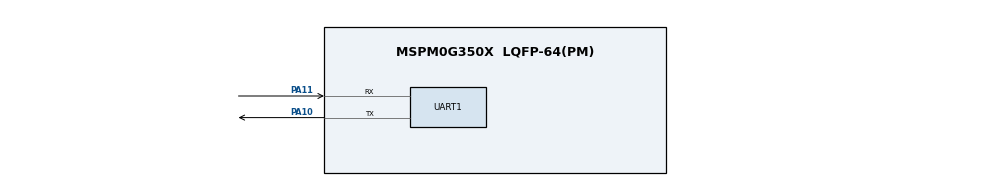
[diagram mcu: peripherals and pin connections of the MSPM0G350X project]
/**
 * @cliArgs --device "MSPM0G350X" --package "LQFP-64(PM)" --part "Default" --product "mspm0_sdk@2.01.00.03"
 * @versions {"tool":"1.20.0+3587"}
 */

/**
 * Import the modules used in this configuration.
 */
const GPIO    = scripting.addModule("/ti/driverlib/GPIO", {}, false);
const GPIO1   = GPIO.addInstance();
const GPIO2   = GPIO.addInstance();
const GPIO3   = GPIO.addInstance();
const SYSCTL  = scripting.addModule("/ti/driverlib/SYSCTL");
const SYSTICK = scripting.addModule("/ti/driverlib/SYSTICK");
const TIMER   = scripting.addModule("/ti/driverlib/TIMER", {}, false);
const TIMER1  = TIMER.addInstance();
const UART    = scripting.addModule("/ti/driverlib/UART", {}, false);
const UART1   = UART.addInstance();

/**
 * Write custom configuration values to the imported modules.
 */
const divider7       = system.clockTree["PLL_PDIV"];
divider7.divideValue = 2;

const divider9       = system.clockTree["UDIV"];
divider9.divideValue = 2;

const gate7  = system.clockTree["MFCLKGATE"];
gate7.enable = true;

const multiplier2         = system.clockTree["PLL_QDIV"];
multiplier2.multiplyValue = 5;

const mux8       = system.clockTree["HSCLKMUX"];
mux8.inputSelect = "HSCLKMUX_SYSPLL2X";

GPIO1.$name                              = "LED1";
GPIO1.port                               = "PORTB";
GPIO1.associatedPins[0].$name            = "PIN_0";
GPIO1.associatedPins[0].internalResistor = "PULL_DOWN";
GPIO1.associatedPins[0].assignedPin      = "9";

const Board = scripting.addModule("/ti/driverlib/Board", {}, false);

GPIO2.$name                         = "ENCODERA";
GPIO2.port                          = "PORTA";
GPIO2.associatedPins.create(2);
GPIO2.associatedPins[0].direction   = "INPUT";
GPIO2.associatedPins[0].interruptEn = true;
GPIO2.associatedPins[0].polarity    = "RISE";
GPIO2.associatedPins[0].$name       = "E1A";
GPIO2.associatedPins[0].assignedPin = "25";
GPIO2.associatedPins[1].direction   = "INPUT";
GPIO2.associatedPins[1].interruptEn = true;
GPIO2.associatedPins[1].polarity    = "RISE";
GPIO2.associatedPins[1].$name       = "E1B";
GPIO2.associatedPins[1].assignedPin = "26";

GPIO3.$name                         = "ENCODERB";
GPIO3.port                          = "PORTB";
GPIO3.associatedPins.create(2);
GPIO3.associatedPins[0].$name       = "E2A";
GPIO3.associatedPins[0].direction   = "INPUT";
GPIO3.associatedPins[0].interruptEn = true;
GPIO3.associatedPins[0].polarity    = "RISE";
GPIO3.associatedPins[0].assignedPin = "20";
GPIO3.associatedPins[1].$name       = "E2B";
GPIO3.associatedPins[1].direction   = "INPUT";
GPIO3.associatedPins[1].interruptEn = true;
GPIO3.associatedPins[1].polarity    = "RISE";
GPIO3.associatedPins[1].assignedPin = "24";

SYSCTL.forceDefaultClkConfig = true;
SYSCTL.clockTreeEn           = true;

SYSTICK.periodEnable      = true;
SYSTICK.systickEnable     = true;
SYSTICK.interruptPriority = "0";
SYSTICK.period            = 16777216;

TIMER1.$name            = "TIMER_0";
TIMER1.timerClkDiv      = 8;
TIMER1.timerClkPrescale = 200;
TIMER1.timerPeriod      = "5 ms";
TIMER1.timerStartTimer  = true;
TIMER1.timerMode        = "PERIODIC";
TIMER1.interrupts       = ["ZERO"];

UART1.$name                    = "UART_0";
UART1.enabledInterrupts        = ["RX"];
UART1.uartClkSrc               = "MFCLK";
UART1.peripheral.$assign       = "UART0";
UART1.peripheral.rxPin.$assign = "PA11";
UART1.peripheral.txPin.$assign = "PA10";
UART1.txPinConfig.$name        = "ti_driverlib_gpio_GPIOPinGeneric0";
UART1.rxPinConfig.$name        = "ti_driverlib_gpio_GPIOPinGeneric1";

/**
 * Pinmux solution for unlocked pins/peripherals. This ensures that minor changes to the automatic solver in a future
 * version of the tool will not impact the pinmux you originally saw.  These lines can be completely deleted in order to
 * re-solve from scratch.
 */
GPIO1.associatedPins[0].pin.$suggestSolution = "PB9";
Board.peripheral.$suggestSolution            = "DEBUGSS";
Board.peripheral.swclkPin.$suggestSolution   = "PA20";
Board.peripheral.swdioPin.$suggestSolution   = "PA19";
GPIO2.associatedPins[0].pin.$suggestSolution = "PA25";
GPIO2.associatedPins[1].pin.$suggestSolution = "PA26";
GPIO3.associatedPins[0].pin.$suggestSolution = "PB20";
GPIO3.associatedPins[1].pin.$suggestSolution = "PB24";
TIMER1.peripheral.$suggestSolution           = "TIMA0";
